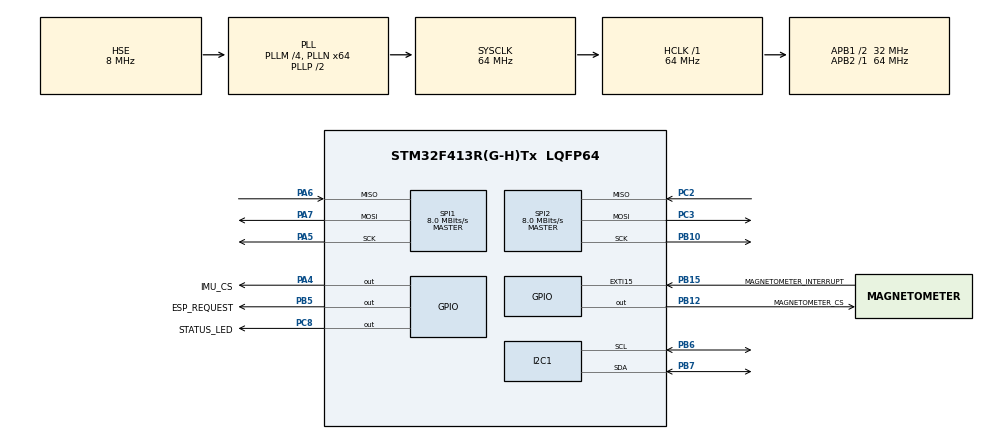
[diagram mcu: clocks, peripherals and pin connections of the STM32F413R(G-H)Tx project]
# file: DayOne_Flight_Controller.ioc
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Dma.I2C1_RX.4.Direction=DMA_PERIPH_TO_MEMORY
Dma.I2C1_RX.4.FIFOMode=DMA_FIFOMODE_DISABLE
Dma.I2C1_RX.4.Instance=DMA1_Stream0
Dma.I2C1_RX.4.MemDataAlignment=DMA_MDATAALIGN_BYTE
Dma.I2C1_RX.4.MemInc=DMA_MINC_ENABLE
Dma.I2C1_RX.4.Mode=DMA_NORMAL
Dma.I2C1_RX.4.PeriphDataAlignment=DMA_PDATAALIGN_BYTE
Dma.I2C1_RX.4.PeriphInc=DMA_PINC_DISABLE
Dma.I2C1_RX.4.Priority=DMA_PRIORITY_LOW
Dma.I2C1_TX.5.Direction=DMA_MEMORY_TO_PERIPH
Dma.I2C1_TX.5.FIFOMode=DMA_FIFOMODE_DISABLE
Dma.I2C1_TX.5.Instance=DMA1_Stream1
Dma.I2C1_TX.5.MemDataAlignment=DMA_MDATAALIGN_BYTE
Dma.I2C1_TX.5.MemInc=DMA_MINC_ENABLE
Dma.I2C1_TX.5.Mode=DMA_NORMAL
Dma.I2C1_TX.5.PeriphDataAlignment=DMA_PDATAALIGN_BYTE
Dma.I2C1_TX.5.PeriphInc=DMA_PINC_DISABLE
Dma.I2C1_TX.5.Priority=DMA_PRIORITY_LOW
Dma.Request0=SPI1_RX
Dma.Request1=SPI1_TX
Dma.Request2=SPI2_RX
Dma.Request3=SPI2_TX
Dma.Request4=I2C1_RX
Dma.Request5=I2C1_TX
Dma.SPI1_RX.0.Direction=DMA_PERIPH_TO_MEMORY
Dma.SPI1_RX.0.FIFOMode=DMA_FIFOMODE_DISABLE
Dma.SPI1_RX.0.Instance=DMA2_Stream0
Dma.SPI1_RX.0.MemDataAlignment=DMA_MDATAALIGN_BYTE
Dma.SPI1_RX.0.MemInc=DMA_MINC_ENABLE
Dma.SPI1_RX.0.Mode=DMA_NORMAL
Dma.SPI1_RX.0.PeriphDataAlignment=DMA_PDATAALIGN_BYTE
Dma.SPI1_RX.0.PeriphInc=DMA_PINC_DISABLE
Dma.SPI1_RX.0.Priority=DMA_PRIORITY_HIGH
Dma.SPI1_TX.1.Direction=DMA_MEMORY_TO_PERIPH
Dma.SPI1_TX.1.FIFOMode=DMA_FIFOMODE_DISABLE
Dma.SPI1_TX.1.Instance=DMA2_Stream2
Dma.SPI1_TX.1.MemDataAlignment=DMA_MDATAALIGN_BYTE
Dma.SPI1_TX.1.MemInc=DMA_MINC_ENABLE
Dma.SPI1_TX.1.Mode=DMA_NORMAL
Dma.SPI1_TX.1.PeriphDataAlignment=DMA_PDATAALIGN_BYTE
Dma.SPI1_TX.1.PeriphInc=DMA_PINC_DISABLE
Dma.SPI1_TX.1.Priority=DMA_PRIORITY_HIGH
Dma.SPI2_RX.2.Direction=DMA_PERIPH_TO_MEMORY
Dma.SPI2_RX.2.FIFOMode=DMA_FIFOMODE_DISABLE
Dma.SPI2_RX.2.Instance=DMA1_Stream3
Dma.SPI2_RX.2.MemDataAlignment=DMA_MDATAALIGN_BYTE
Dma.SPI2_RX.2.MemInc=DMA_MINC_ENABLE
Dma.SPI2_RX.2.Mode=DMA_NORMAL
Dma.SPI2_RX.2.PeriphDataAlignment=DMA_PDATAALIGN_BYTE
Dma.SPI2_RX.2.PeriphInc=DMA_PINC_DISABLE
Dma.SPI2_RX.2.Priority=DMA_PRIORITY_HIGH
Dma.SPI2_TX.3.Direction=DMA_MEMORY_TO_PERIPH
Dma.SPI2_TX.3.FIFOMode=DMA_FIFOMODE_DISABLE
Dma.SPI2_TX.3.Instance=DMA1_Stream4
Dma.SPI2_TX.3.MemDataAlignment=DMA_MDATAALIGN_BYTE
Dma.SPI2_TX.3.MemInc=DMA_MINC_ENABLE
Dma.SPI2_TX.3.Mode=DMA_NORMAL
Dma.SPI2_TX.3.PeriphDataAlignment=DMA_PDATAALIGN_BYTE
Dma.SPI2_TX.3.PeriphInc=DMA_PINC_DISABLE
Dma.SPI2_TX.3.Priority=DMA_PRIORITY_HIGH
I2C1.OwnAddress=0x67
Mcu.Family=STM32F4
Mcu.Name=STM32F413R(G-H)Tx
Mcu.Package=LQFP64
NVIC.DMA1_Stream0_IRQn=true\:0\:0\:false\:false\:true\:false\:true\:true
NVIC.DMA1_Stream1_IRQn=true\:0\:0\:false\:false\:true\:false\:true\:true
NVIC.DMA1_Stream3_IRQn=true\:0\:0\:false\:false\:true\:false\:true\:true
NVIC.DMA1_Stream4_IRQn=true\:0\:0\:false\:false\:true\:false\:true\:true
NVIC.DMA2_Stream0_IRQn=true\:0\:0\:false\:false\:true\:false\:true\:true
NVIC.DMA2_Stream2_IRQn=true\:0\:0\:false\:false\:true\:false\:true\:true
NVIC.EXTI15_10_IRQn=true\:0\:0\:false\:false\:true\:true\:true\:true
NVIC.I2C1_ER_IRQn=true\:0\:0\:false\:false\:true\:true\:true\:true
NVIC.I2C1_EV_IRQn=true\:0\:0\:false\:false\:true\:true\:true\:true
NVIC.PriorityGroup=NVIC_PRIORITYGROUP_4
NVIC.SPI1_IRQn=true\:0\:0\:false\:false\:true\:true\:true\:true
NVIC.SPI2_IRQn=true\:0\:0\:false\:false\:true\:true\:true\:true
NVIC.TIM2_IRQn=true\:0\:0\:false\:false\:true\:true\:true\:true
PA4.GPIO_Label=IMU_CS
PA4.PinState=GPIO_PIN_SET
PA4.Signal=GPIO_Output
PA5.Mode=Full_Duplex_Master
PA5.Signal=SPI1_SCK
PA6.Mode=Full_Duplex_Master
PA6.Signal=SPI1_MISO
PA7.Mode=Full_Duplex_Master
PA7.Signal=SPI1_MOSI
PB10.Mode=Full_Duplex_Master
PB10.Signal=SPI2_SCK
PB12.GPIO_Label=MAGNETOMETER_CS
PB12.PinState=GPIO_PIN_SET
PB12.Signal=GPIO_Output
PB15.GPIO_Label=MAGNETOMETER_INTERRUPT
PB15.GPIO_ModeDefaultEXTI=GPIO_MODE_IT_RISING
PB15.GPIO_PuPd=GPIO_NOPULL
PB15.Signal=GPXTI15
PB5.GPIO_Label=ESP_REQUEST
PB5.Signal=GPIO_Output
PB6.Mode=I2C
PB6.Signal=I2C1_SCL
PB7.Mode=I2C
PB7.Signal=I2C1_SDA
PC2.Mode=Full_Duplex_Master
PC2.Signal=SPI2_MISO
PC3.Mode=Full_Duplex_Master
PC3.Signal=SPI2_MOSI
PC8.GPIO_Label=STATUS_LED
PC8.Signal=GPIO_Output
PH0\ -\ OSC_IN.Mode=HSE-External-Oscillator
PH0\ -\ OSC_IN.Signal=RCC_OSC_IN
PH1\ -\ OSC_OUT.Mode=HSE-External-Oscillator
PH1\ -\ OSC_OUT.Signal=RCC_OSC_OUT
ProjectManager.HeapSize=0x200
ProjectManager.StackSize=0x400
ProjectManager.TargetToolchain=STM32CubeIDE
RCC.AHBFreq_Value=64000000
RCC.APB1CLKDivider=RCC_HCLK_DIV2
RCC.APB1Freq_Value=32000000
RCC.APB1TimFreq_Value=64000000
RCC.APB2Freq_Value=64000000
RCC.APB2TimFreq_Value=64000000
RCC.CortexFreq_Value=64000000
RCC.HCLKFreq_Value=64000000
RCC.HSE_VALUE=8000000
RCC.PLLM=4
RCC.PLLN=64
RCC.PLLSourceVirtual=RCC_PLLSOURCE_HSE
RCC.SYSCLKFreq_VALUE=64000000
RCC.SYSCLKSource=RCC_SYSCLKSOURCE_PLLCLK
RCC.USBFreq_Value=64000000
RCC.VCOOutputFreq_Value=128000000
SPI1.BaudRatePrescaler=SPI_BAUDRATEPRESCALER_8
SPI1.CLKPhase=SPI_PHASE_1EDGE
SPI1.CLKPolarity=SPI_POLARITY_LOW
SPI1.CalculateBaudRate=8.0 MBits/s
SPI1.Direction=SPI_DIRECTION_2LINES
SPI1.Mode=SPI_MODE_MASTER
SPI1.VirtualType=VM_MASTER
SPI2.BaudRatePrescaler=SPI_BAUDRATEPRESCALER_4
SPI2.CalculateBaudRate=8.0 MBits/s
SPI2.Direction=SPI_DIRECTION_2LINES
SPI2.Mode=SPI_MODE_MASTER
SPI2.VirtualType=VM_MASTER
TIM2.AutoReloadPreload=TIM_AUTORELOAD_PRELOAD_DISABLE
TIM2.Period=1000-1
TIM2.Prescaler=63
VP_TIM2_VS_ClockSourceINT.Mode=Internal
board=custom

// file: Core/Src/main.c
/* USER CODE BEGIN Header */
/**
  ******************************************************************************
  * @file           : main.c
  * @brief          : Main program body
  ******************************************************************************
  * @attention
  *
  * Copyright (c) 2026 STMicroelectronics.
  * All rights reserved.
  *
  * This software is licensed under terms that can be found in the LICENSE file
  * in the root directory of this software component.
  * If no LICENSE file comes with this software, it is provided AS-IS.
  *
  ******************************************************************************
  */
/* USER CODE END Header */
#include "main.h"

/* USER CODE BEGIN Includes */
#include "Application/inc/Application.hpp"
/* USER CODE END Includes */

I2C_HandleTypeDef hi2c1;
DMA_HandleTypeDef hdma_i2c1_rx;
DMA_HandleTypeDef hdma_i2c1_tx;

SPI_HandleTypeDef hspi1;
SPI_HandleTypeDef hspi2;
DMA_HandleTypeDef hdma_spi1_rx;
DMA_HandleTypeDef hdma_spi1_tx;
DMA_HandleTypeDef hdma_spi2_rx;
DMA_HandleTypeDef hdma_spi2_tx;

TIM_HandleTypeDef htim2;

void SystemClock_Config(void);
static void MX_GPIO_Init(void);
static void MX_DMA_Init(void);
static void MX_SPI1_Init(void);
static void MX_SPI2_Init(void);
static void MX_TIM2_Init(void);
static void MX_I2C1_Init(void);

int main(void)
{

  /* MCU Configuration--------------------------------------------------------*/

  /* Reset of all peripherals, Initializes the Flash interface and the Systick. */
  HAL_Init();

  /* Configure the system clock */
  SystemClock_Config();

  /* Initialize all configured peripherals */
  MX_GPIO_Init();
  MX_DMA_Init();
  MX_SPI1_Init();
  MX_SPI2_Init();
  MX_TIM2_Init();
  MX_I2C1_Init();
  /* USER CODE BEGIN 2 */
  App_Init(&hspi1, &hspi2, &hi2c1);
  HAL_TIM_Base_Start_IT(&htim2);
  /* USER CODE END 2 */

  /* Infinite loop */
  while (1)
  {

  }
}

void SystemClock_Config(void)
{
  RCC_OscInitTypeDef RCC_OscInitStruct = {0};
  RCC_ClkInitTypeDef RCC_ClkInitStruct = {0};

  /** Configure the main internal regulator output voltage
  */
  __HAL_RCC_PWR_CLK_ENABLE();
  __HAL_PWR_VOLTAGESCALING_CONFIG(PWR_REGULATOR_VOLTAGE_SCALE1);

  /** Initializes the RCC Oscillators according to the specified parameters
  * in the RCC_OscInitTypeDef structure.
  */
  RCC_OscInitStruct.OscillatorType = RCC_OSCILLATORTYPE_HSE;
  RCC_OscInitStruct.HSEState = RCC_HSE_ON;
  RCC_OscInitStruct.PLL.PLLState = RCC_PLL_ON;
  RCC_OscInitStruct.PLL.PLLSource = RCC_PLLSOURCE_HSE;
  RCC_OscInitStruct.PLL.PLLM = 4;
  RCC_OscInitStruct.PLL.PLLN = 64;
  RCC_OscInitStruct.PLL.PLLP = RCC_PLLP_DIV2;
  RCC_OscInitStruct.PLL.PLLQ = 2;
  RCC_OscInitStruct.PLL.PLLR = 2;
  if (HAL_RCC_OscConfig(&RCC_OscInitStruct) != HAL_OK)
  {
    Error_Handler();
  }

  /** Initializes the CPU, AHB and APB buses clocks
  */
  RCC_ClkInitStruct.ClockType = RCC_CLOCKTYPE_HCLK|RCC_CLOCKTYPE_SYSCLK
                              |RCC_CLOCKTYPE_PCLK1|RCC_CLOCKTYPE_PCLK2;
  RCC_ClkInitStruct.SYSCLKSource = RCC_SYSCLKSOURCE_PLLCLK;
  RCC_ClkInitStruct.AHBCLKDivider = RCC_SYSCLK_DIV1;
  RCC_ClkInitStruct.APB1CLKDivider = RCC_HCLK_DIV2;
  RCC_ClkInitStruct.APB2CLKDivider = RCC_HCLK_DIV1;

  if (HAL_RCC_ClockConfig(&RCC_ClkInitStruct, FLASH_LATENCY_2) != HAL_OK)
  {
    Error_Handler();
  }
}

static void MX_I2C1_Init(void)
{

  hi2c1.Instance = I2C1;
  hi2c1.Init.ClockSpeed = 100000;
  hi2c1.Init.DutyCycle = I2C_DUTYCYCLE_2;
  hi2c1.Init.OwnAddress1 = 206;
  hi2c1.Init.AddressingMode = I2C_ADDRESSINGMODE_7BIT;
  hi2c1.Init.DualAddressMode = I2C_DUALADDRESS_DISABLE;
  hi2c1.Init.OwnAddress2 = 0;
  hi2c1.Init.GeneralCallMode = I2C_GENERALCALL_DISABLE;
  hi2c1.Init.NoStretchMode = I2C_NOSTRETCH_DISABLE;
  if (HAL_I2C_Init(&hi2c1) != HAL_OK)
  {
    Error_Handler();
  }

}

static void MX_SPI1_Init(void)
{

  /* SPI1 parameter configuration*/
  hspi1.Instance = SPI1;
  hspi1.Init.Mode = SPI_MODE_MASTER;
  hspi1.Init.Direction = SPI_DIRECTION_2LINES;
  hspi1.Init.DataSize = SPI_DATASIZE_8BIT;
  hspi1.Init.CLKPolarity = SPI_POLARITY_LOW;
  hspi1.Init.CLKPhase = SPI_PHASE_1EDGE;
  hspi1.Init.NSS = SPI_NSS_SOFT;
  hspi1.Init.BaudRatePrescaler = SPI_BAUDRATEPRESCALER_8;
  hspi1.Init.FirstBit = SPI_FIRSTBIT_MSB;
  hspi1.Init.TIMode = SPI_TIMODE_DISABLE;
  hspi1.Init.CRCCalculation = SPI_CRCCALCULATION_DISABLE;
  hspi1.Init.CRCPolynomial = 10;
  if (HAL_SPI_Init(&hspi1) != HAL_OK)
  {
    Error_Handler();
  }

}

static void MX_SPI2_Init(void)
{

  /* SPI2 parameter configuration*/
  hspi2.Instance = SPI2;
  hspi2.Init.Mode = SPI_MODE_MASTER;
  hspi2.Init.Direction = SPI_DIRECTION_2LINES;
  hspi2.Init.DataSize = SPI_DATASIZE_8BIT;
  hspi2.Init.CLKPolarity = SPI_POLARITY_LOW;
  hspi2.Init.CLKPhase = SPI_PHASE_1EDGE;
  hspi2.Init.NSS = SPI_NSS_SOFT;
  hspi2.Init.BaudRatePrescaler = SPI_BAUDRATEPRESCALER_4;
  hspi2.Init.FirstBit = SPI_FIRSTBIT_MSB;
  hspi2.Init.TIMode = SPI_TIMODE_DISABLE;
  hspi2.Init.CRCCalculation = SPI_CRCCALCULATION_DISABLE;
  hspi2.Init.CRCPolynomial = 10;
  if (HAL_SPI_Init(&hspi2) != HAL_OK)
  {
    Error_Handler();
  }

}

static void MX_TIM2_Init(void)
{

  TIM_ClockConfigTypeDef sClockSourceConfig = {0};
  TIM_MasterConfigTypeDef sMasterConfig = {0};

  htim2.Instance = TIM2;
  htim2.Init.Prescaler = 63;
  htim2.Init.CounterMode = TIM_COUNTERMODE_UP;
  htim2.Init.Period = 1000-1;
  htim2.Init.ClockDivision = TIM_CLOCKDIVISION_DIV1;
  htim2.Init.AutoReloadPreload = TIM_AUTORELOAD_PRELOAD_DISABLE;
  if (HAL_TIM_Base_Init(&htim2) != HAL_OK)
  {
    Error_Handler();
  }
  sClockSourceConfig.ClockSource = TIM_CLOCKSOURCE_INTERNAL;
  if (HAL_TIM_ConfigClockSource(&htim2, &sClockSourceConfig) != HAL_OK)
  {
    Error_Handler();
  }
  sMasterConfig.MasterOutputTrigger = TIM_TRGO_RESET;
  sMasterConfig.MasterSlaveMode = TIM_MASTERSLAVEMODE_DISABLE;
  if (HAL_TIMEx_MasterConfigSynchronization(&htim2, &sMasterConfig) != HAL_OK)
  {
    Error_Handler();
  }

}

static void MX_DMA_Init(void)
{

  /* DMA controller clock enable */
  __HAL_RCC_DMA2_CLK_ENABLE();
  __HAL_RCC_DMA1_CLK_ENABLE();

  /* DMA interrupt init */
  /* DMA1_Stream0_IRQn interrupt configuration */
  HAL_NVIC_SetPriority(DMA1_Stream0_IRQn, 0, 0);
  HAL_NVIC_EnableIRQ(DMA1_Stream0_IRQn);
  /* DMA1_Stream1_IRQn interrupt configuration */
  HAL_NVIC_SetPriority(DMA1_Stream1_IRQn, 0, 0);
  HAL_NVIC_EnableIRQ(DMA1_Stream1_IRQn);
  /* DMA1_Stream3_IRQn interrupt configuration */
  HAL_NVIC_SetPriority(DMA1_Stream3_IRQn, 0, 0);
  HAL_NVIC_EnableIRQ(DMA1_Stream3_IRQn);
  /* DMA1_Stream4_IRQn interrupt configuration */
  HAL_NVIC_SetPriority(DMA1_Stream4_IRQn, 0, 0);
  HAL_NVIC_EnableIRQ(DMA1_Stream4_IRQn);
  /* DMA2_Stream0_IRQn interrupt configuration */
  HAL_NVIC_SetPriority(DMA2_Stream0_IRQn, 0, 0);
  HAL_NVIC_EnableIRQ(DMA2_Stream0_IRQn);
  /* DMA2_Stream2_IRQn interrupt configuration */
  HAL_NVIC_SetPriority(DMA2_Stream2_IRQn, 0, 0);
  HAL_NVIC_EnableIRQ(DMA2_Stream2_IRQn);

}

static void MX_GPIO_Init(void)
{
  GPIO_InitTypeDef GPIO_InitStruct = {0};

  /* GPIO Ports Clock Enable */
  __HAL_RCC_GPIOH_CLK_ENABLE();
  __HAL_RCC_GPIOC_CLK_ENABLE();
  __HAL_RCC_GPIOA_CLK_ENABLE();
  __HAL_RCC_GPIOB_CLK_ENABLE();

  /*Configure GPIO pin Output Level */
  HAL_GPIO_WritePin(IMU_CS_GPIO_Port, IMU_CS_Pin, GPIO_PIN_SET);

  /*Configure GPIO pin Output Level */
  HAL_GPIO_WritePin(MAGNETOMETER_CS_GPIO_Port, MAGNETOMETER_CS_Pin, GPIO_PIN_SET);

  /*Configure GPIO pin Output Level */
  HAL_GPIO_WritePin(STATUS_LED_GPIO_Port, STATUS_LED_Pin, GPIO_PIN_RESET);

  /*Configure GPIO pin Output Level */
  HAL_GPIO_WritePin(ESP_REQUEST_GPIO_Port, ESP_REQUEST_Pin, GPIO_PIN_RESET);

  /*Configure GPIO pin : IMU_CS_Pin */
  GPIO_InitStruct.Pin = IMU_CS_Pin;
  GPIO_InitStruct.Mode = GPIO_MODE_OUTPUT_PP;
  GPIO_InitStruct.Pull = GPIO_NOPULL;
  GPIO_InitStruct.Speed = GPIO_SPEED_FREQ_LOW;
  HAL_GPIO_Init(IMU_CS_GPIO_Port, &GPIO_InitStruct);

  /*Configure GPIO pins : MAGNETOMETER_CS_Pin ESP_REQUEST_Pin */
  GPIO_InitStruct.Pin = MAGNETOMETER_CS_Pin|ESP_REQUEST_Pin;
  GPIO_InitStruct.Mode = GPIO_MODE_OUTPUT_PP;
  GPIO_InitStruct.Pull = GPIO_NOPULL;
  GPIO_InitStruct.Speed = GPIO_SPEED_FREQ_LOW;
  HAL_GPIO_Init(GPIOB, &GPIO_InitStruct);

  /*Configure GPIO pin : MAGNETOMETER_INTERRUPT_Pin */
  GPIO_InitStruct.Pin = MAGNETOMETER_INTERRUPT_Pin;
  GPIO_InitStruct.Mode = GPIO_MODE_IT_RISING;
  GPIO_InitStruct.Pull = GPIO_NOPULL;
  HAL_GPIO_Init(MAGNETOMETER_INTERRUPT_GPIO_Port, &GPIO_InitStruct);

  /*Configure GPIO pin : STATUS_LED_Pin */
  GPIO_InitStruct.Pin = STATUS_LED_Pin;
  GPIO_InitStruct.Mode = GPIO_MODE_OUTPUT_PP;
  GPIO_InitStruct.Pull = GPIO_NOPULL;
  GPIO_InitStruct.Speed = GPIO_SPEED_FREQ_LOW;
  HAL_GPIO_Init(STATUS_LED_GPIO_Port, &GPIO_InitStruct);

  /* EXTI interrupt init*/
  HAL_NVIC_SetPriority(EXTI15_10_IRQn, 0, 0);
  HAL_NVIC_EnableIRQ(EXTI15_10_IRQn);

}

void Error_Handler(void)
{
  __disable_irq();
  while (1)
  {
  }
}
